# LPC176x5x register map
File version: 0.2
CPU: CM3 r0p0, little endian, no MPU, no FPU, 0x5 interrupt priority bits, 0x0 interrupts
Registers are 32-bit, read-write, no defined reset value unless marked. A register's access mark holds for its fields unless they carry their own. Offsets are from the block's base; [hi:lo] are bit positions; {n}, {i} and the like mark numbered series; <NAME> marks a mode.

## USB — USB device/host/OTG controller
Base 0x50008000
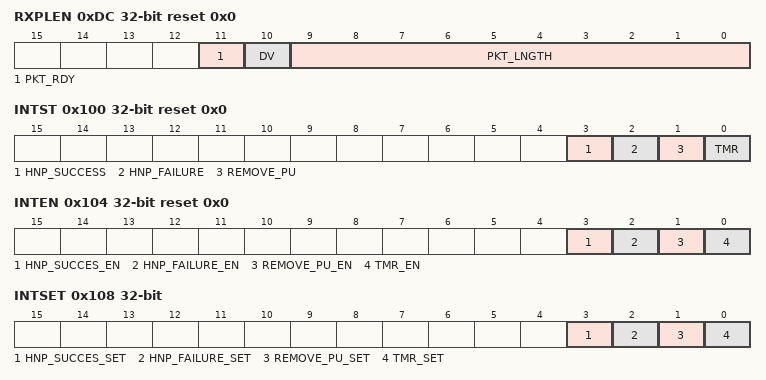
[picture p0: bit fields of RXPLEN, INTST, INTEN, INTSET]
0xDC RXPLEN ro reset 0x0 — USB Receive Packet Length
  [11] PKT_RDY — The PKT_LNGTH field is valid and the packet is ready for reading.
  [10] DV — Data valid. This bit is useful for isochronous endpoints. Non-isochronous endpoints do not raise an interrupt when an erroneous data packet is received. But invalid data packet can be produced with a bus reset. For isochronous endpoints, data transfer will happen even if an erroneous packet is received. In this case DV bit will not be set for the packet.
    0=DATA_IS_INVALID_; 1=DATA_IS_VALID_
  [9:0] PKT_LNGTH — The remaining number of bytes to be read from the currently selected endpoint's buffer. When this field decrements to 0, the RxENDPKT bit will be set in USBDevIntSt.
0x100 INTST ro reset 0x0 — OTG Interrupt Status
  [3] HNP_SUCCESS — HNP succeeded. This bit is set by hardware to indicate that the HNP switching has succeeded.
  [2] HNP_FAILURE — HNP failed. This bit is set by hardware to indicate that the HNP switching has failed.
  [1] REMOVE_PU — Remove pull-up. This bit is set by hardware to indicate that software needs to disable the D+ pull-up resistor.
  [0] TMR — Timer time-out.
0x104 INTEN reset 0x0 — OTG Interrupt Enable
  [3] HNP_SUCCES_EN — 1 = enable the corresponding bit in the IntSt register.
  [2] HNP_FAILURE_EN — 1 = enable the corresponding bit in the IntSt register.
  [1] REMOVE_PU_EN — 1 = enable the corresponding bit in the IntSt register.
  [0] TMR_EN — 1 = enable the corresponding bit in the IntSt register.
0x108 INTSET wo — OTG Interrupt Set
  [3] HNP_SUCCES_SET — 0 = no effect. 1 = set the corresponding bit in the IntSt register.
  [2] HNP_FAILURE_SET — 0 = no effect. 1 = set the corresponding bit in the IntSt register.
  [1] REMOVE_PU_SET — 0 = no effect. 1 = set the corresponding bit in the IntSt register.
  [0] TMR_SET — 0 = no effect. 1 = set the corresponding bit in the IntSt register.
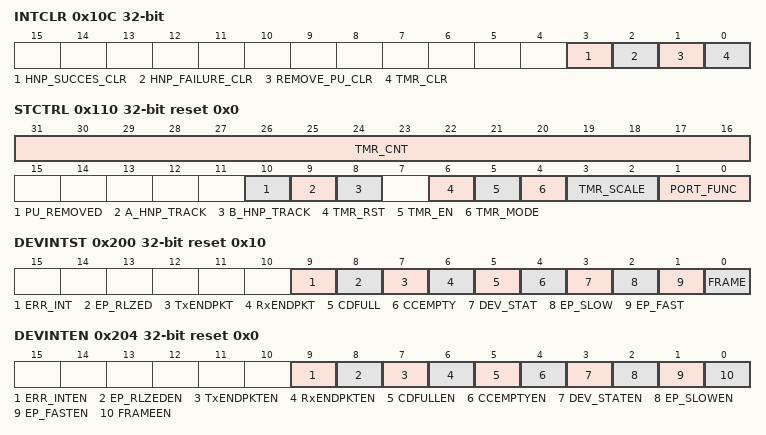
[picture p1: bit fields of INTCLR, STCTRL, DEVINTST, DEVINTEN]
0x10C INTCLR wo — OTG Interrupt Clear
  [3] HNP_SUCCES_CLR — 0 = no effect. 1 = clear the corresponding bit in the IntSt register.
  [2] HNP_FAILURE_CLR — 0 = no effect. 1 = clear the corresponding bit in the IntSt register.
  [1] REMOVE_PU_CLR — 0 = no effect. 1 = clear the corresponding bit in the IntSt register.
  [0] TMR_CLR — 0 = no effect. 1 = clear the corresponding bit in the IntSt register.
0x110 STCTRL reset 0x0 — OTG Status and Control and USB port select
  [31:16] TMR_CNT — Current timer count value.
  [10] PU_REMOVED — When the B-device changes its role from peripheral to host, software sets this bit when it removes the D+ pull-up, see Section 14.9. Hardware clears this bit when HNP_SUCCESS or HNP_FAILURE is set.
  [9] A_HNP_TRACK — Enable HNP tracking for A-device (host), see Section 14.9. Hardware clears this bit when HNP_SUCCESS or HNP_FAILURE is set.
  [8] B_HNP_TRACK — Enable HNP tracking for B-device (peripheral), see Section 14.9. Hardware clears this bit when HNP_SUCCESS or HNP_FAILURE is set.
  [6] TMR_RST — Timer reset. Writing one to this bit resets TMR_CNT to 0. This provides a single bit control for the software to restart the timer when the timer is enabled.
  [5] TMR_EN — Timer enable. When set, TMR_CNT increments. When cleared, TMR_CNT is reset to 0.
  [4] TMR_MODE — Timer mode selection. 0: monoshot 1: free running
  [3:2] TMR_SCALE — Timer scale selection. This field determines the duration of each timer count. 00: 10 ms (100 KHz) 01: 100 ms (10 KHz) 10: 1000 ms (1 KHz) 11: Reserved
  [1:0] PORT_FUNC — Controls connection of USB functions (see Figure 51). Bit 0 is set or cleared by hardware when B_HNP_TRACK or A_HNP_TRACK is set and HNP succeeds. See Section 14.9. 00: U1 = device (OTG), U2 = host 01: U1 = host (OTG), U2 = host 10: Reserved 11: U1 = host, U2 = device In a device-only configuration, the following values are allowed: 00: U1 = device. The USB device controller signals are mapped to the U1 port: USB_CONNECT1, USB_UP_LED1, USB_D+1, USB_D-1. 11: U2 = device. The USB device controller signals are mapped to the U2 port: USB_CONNECT2, USB_UP_LED2, USB_D+2, USB_D-2.
0x114 TMR reset 0xFFFF — OTG Timer
  [15:0] TIMEOUT_CNT — The TMR interrupt is set when TMR_CNT reaches this value.
0x200 DEVINTST ro reset 0x10 — USB Device Interrupt Status
  [9] ERR_INT — Error Interrupt. Any bus error interrupt from the USB device. Refer to Section 13.12.9 Read Error Status (Command: 0xFB, Data: read 1 byte) on page 368
  [8] EP_RLZED — Endpoints realized. Set when Realize Endpoint register (USBReEp) or MaxPacketSize register (USBMaxPSize) is updated and the corresponding operation is completed.
  [7] TxENDPKT — The number of data bytes transferred to the endpoint buffer equals the number of bytes programmed in the TxPacket length register (USBTxPLen).
  [6] RxENDPKT — The current packet in the endpoint buffer is transferred to the CPU.
  [5] CDFULL — Command data register (USBCmdData) is full (Data can be read now).
  [4] CCEMPTY — The command code register (USBCmdCode) is empty (New command can be written).
  [3] DEV_STAT — Set when USB Bus reset, USB suspend change or Connect change event occurs. Refer to Section 13.12.6 Set Device Status (Command: 0xFE, Data: write 1 byte) on page 366.
  [2] EP_SLOW — Slow endpoints interrupt. If an Endpoint Interrupt Priority Register (USBEpIntPri) bit is not set, the corresponding endpoint interrupt will be routed to this bit.
  [1] EP_FAST — Fast endpoint interrupt. If an Endpoint Interrupt Priority register (USBEpIntPri) bit is set, the corresponding endpoint interrupt will be routed to this bit.
  [0] FRAME — The frame interrupt occurs every 1 ms. This is used in isochronous packet transfers.
0x204 DEVINTEN reset 0x0 — USB Device Interrupt Enable
  [9] ERR_INTEN — 0 = No interrupt is generated. 1 = An interrupt will be generated when the corresponding bit in the Device Interrupt Status (USBDevIntSt) register (Table 261) is set. By default, the interrupt is routed to the USB_INT_REQ_LP interrupt line. Optionally, either the EP_FAST or FRAME interrupt may be routed to the USB_INT_REQ_HP interrupt line by changing the value of USBDevIntPri.
  [8] EP_RLZEDEN — 0 = No interrupt is generated. 1 = An interrupt will be generated when the corresponding bit in the Device Interrupt Status (USBDevIntSt) register (Table 261) is set. By default, the interrupt is routed to the USB_INT_REQ_LP interrupt line. Optionally, either the EP_FAST or FRAME interrupt may be routed to the USB_INT_REQ_HP interrupt line by changing the value of USBDevIntPri.
  [7] TxENDPKTEN — 0 = No interrupt is generated. 1 = An interrupt will be generated when the corresponding bit in the Device Interrupt Status (USBDevIntSt) register (Table 261) is set. By default, the interrupt is routed to the USB_INT_REQ_LP interrupt line. Optionally, either the EP_FAST or FRAME interrupt may be routed to the USB_INT_REQ_HP interrupt line by changing the value of USBDevIntPri.
  [6] RxENDPKTEN — 0 = No interrupt is generated. 1 = An interrupt will be generated when the corresponding bit in the Device Interrupt Status (USBDevIntSt) register (Table 261) is set. By default, the interrupt is routed to the USB_INT_REQ_LP interrupt line. Optionally, either the EP_FAST or FRAME interrupt may be routed to the USB_INT_REQ_HP interrupt line by changing the value of USBDevIntPri.
  [5] CDFULLEN — 0 = No interrupt is generated. 1 = An interrupt will be generated when the corresponding bit in the Device Interrupt Status (USBDevIntSt) register (Table 261) is set. By default, the interrupt is routed to the USB_INT_REQ_LP interrupt line. Optionally, either the EP_FAST or FRAME interrupt may be routed to the USB_INT_REQ_HP interrupt line by changing the value of USBDevIntPri.
  [4] CCEMPTYEN — 0 = No interrupt is generated. 1 = An interrupt will be generated when the corresponding bit in the Device Interrupt Status (USBDevIntSt) register (Table 261) is set. By default, the interrupt is routed to the USB_INT_REQ_LP interrupt line. Optionally, either the EP_FAST or FRAME interrupt may be routed to the USB_INT_REQ_HP interrupt line by changing the value of USBDevIntPri.
  [3] DEV_STATEN — 0 = No interrupt is generated. 1 = An interrupt will be generated when the corresponding bit in the Device Interrupt Status (USBDevIntSt) register (Table 261) is set. By default, the interrupt is routed to the USB_INT_REQ_LP interrupt line. Optionally, either the EP_FAST or FRAME interrupt may be routed to the USB_INT_REQ_HP interrupt line by changing the value of USBDevIntPri.
  [2] EP_SLOWEN — 0 = No interrupt is generated. 1 = An interrupt will be generated when the corresponding bit in the Device Interrupt Status (USBDevIntSt) register (Table 261) is set. By default, the interrupt is routed to the USB_INT_REQ_LP interrupt line. Optionally, either the EP_FAST or FRAME interrupt may be routed to the USB_INT_REQ_HP interrupt line by changing the value of USBDevIntPri.
  [1] EP_FASTEN — 0 = No interrupt is generated. 1 = An interrupt will be generated when the corresponding bit in the Device Interrupt Status (USBDevIntSt) register (Table 261) is set. By default, the interrupt is routed to the USB_INT_REQ_LP interrupt line. Optionally, either the EP_FAST or FRAME interrupt may be routed to the USB_INT_REQ_HP interrupt line by changing the value of USBDevIntPri.
  [0] FRAMEEN — 0 = No interrupt is generated. 1 = An interrupt will be generated when the corresponding bit in the Device Interrupt Status (USBDevIntSt) register (Table 261) is set. By default, the interrupt is routed to the USB_INT_REQ_LP interrupt line. Optionally, either the EP_FAST or FRAME interrupt may be routed to the USB_INT_REQ_HP interrupt line by changing the value of USBDevIntPri.
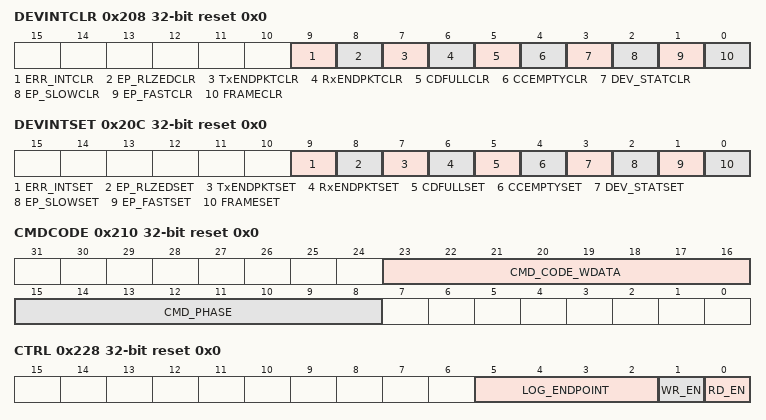
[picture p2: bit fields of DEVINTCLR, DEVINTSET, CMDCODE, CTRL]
0x208 DEVINTCLR wo reset 0x0 — USB Device Interrupt Clear
  [9] ERR_INTCLR — 0 = No effect. 1 = The corresponding bit in USBDevIntSt (Section 13.10.3.2) is cleared.
  [8] EP_RLZEDCLR — 0 = No effect. 1 = The corresponding bit in USBDevIntSt (Section 13.10.3.2) is cleared.
  [7] TxENDPKTCLR — 0 = No effect. 1 = The corresponding bit in USBDevIntSt (Section 13.10.3.2) is cleared.
  [6] RxENDPKTCLR — 0 = No effect. 1 = The corresponding bit in USBDevIntSt (Section 13.10.3.2) is cleared.
  [5] CDFULLCLR — 0 = No effect. 1 = The corresponding bit in USBDevIntSt (Section 13.10.3.2) is cleared.
  [4] CCEMPTYCLR — 0 = No effect. 1 = The corresponding bit in USBDevIntSt (Section 13.10.3.2) is cleared.
  [3] DEV_STATCLR — 0 = No effect. 1 = The corresponding bit in USBDevIntSt (Section 13.10.3.2) is cleared.
  [2] EP_SLOWCLR — 0 = No effect. 1 = The corresponding bit in USBDevIntSt (Section 13.10.3.2) is cleared.
  [1] EP_FASTCLR — 0 = No effect. 1 = The corresponding bit in USBDevIntSt (Section 13.10.3.2) is cleared.
  [0] FRAMECLR — 0 = No effect. 1 = The corresponding bit in USBDevIntSt (Section 13.10.3.2) is cleared.
0x20C DEVINTSET wo reset 0x0 — USB Device Interrupt Set
  [9] ERR_INTSET — 0 = No effect. 1 = The corresponding bit in USBDevIntSt (Section 13.10.3.2) is set.
  [8] EP_RLZEDSET — 0 = No effect. 1 = The corresponding bit in USBDevIntSt (Section 13.10.3.2) is set.
  [7] TxENDPKTSET — 0 = No effect. 1 = The corresponding bit in USBDevIntSt (Section 13.10.3.2) is set.
  [6] RxENDPKTSET — 0 = No effect. 1 = The corresponding bit in USBDevIntSt (Section 13.10.3.2) is set.
  [5] CDFULLSET — 0 = No effect. 1 = The corresponding bit in USBDevIntSt (Section 13.10.3.2) is set.
  [4] CCEMPTYSET — 0 = No effect. 1 = The corresponding bit in USBDevIntSt (Section 13.10.3.2) is set.
  [3] DEV_STATSET — 0 = No effect. 1 = The corresponding bit in USBDevIntSt (Section 13.10.3.2) is set.
  [2] EP_SLOWSET — 0 = No effect. 1 = The corresponding bit in USBDevIntSt (Section 13.10.3.2) is set.
  [1] EP_FASTSET — 0 = No effect. 1 = The corresponding bit in USBDevIntSt (Section 13.10.3.2) is set.
  [0] FRAMESET — 0 = No effect. 1 = The corresponding bit in USBDevIntSt (Section 13.10.3.2) is set.
0x210 CMDCODE wo reset 0x0 — USB Command Code
  [23:16] CMD_CODE_WDATA — This is a multi-purpose field. When CMD_PHASE is Command or Read, this field contains the code for the command (CMD_CODE). When CMD_PHASE is Write, this field contains the command write data (CMD_WDATA).
  [15:8] CMD_PHASE — The command phase:
    2=READ; 1=WRITE; 5=COMMAND
0x214 CMDDATA ro reset 0x0 — USB Command Data
  [7:0] CMD_RDATA — Command Read Data.
0x218 RXDATA ro reset 0x0 — USB Receive Data
  [31:0] RX_DATA — Data received.
0x21C TXDATA wo reset 0x0 — USB Transmit Data
  [31:0] TX_DATA — Transmit Data.
0x224 TXPLEN wo reset 0x0 — USB Transmit Packet Length
  [9:0] PKT_LNGTH — The remaining number of bytes to be written to the selected endpoint buffer. This field is decremented by 4 by hardware after each write to USBTxData. When this field decrements to 0, the TxENDPKT bit will be set in USBDevIntSt.
0x228 CTRL reset 0x0 — USB Control
  [5:2] LOG_ENDPOINT — Logical Endpoint number.
  [1] WR_EN — Write mode control. Enables writing data to the IN endpoint buffer for the endpoint specified in the LOG_ENDPOINT field using the USBTxData register. This bit is cleared by hardware when the number of bytes in USBTxLen have been sent.
    0=DISABLED_; 1=ENABLED_
  [0] RD_EN — Read mode control. Enables reading data from the OUT endpoint buffer for the endpoint specified in the LOG_ENDPOINT field using the USBRxData register. This bit is cleared by hardware when the last word of the current packet is read from USBRxData.
    0=DISABLED_; 1=ENABLED_
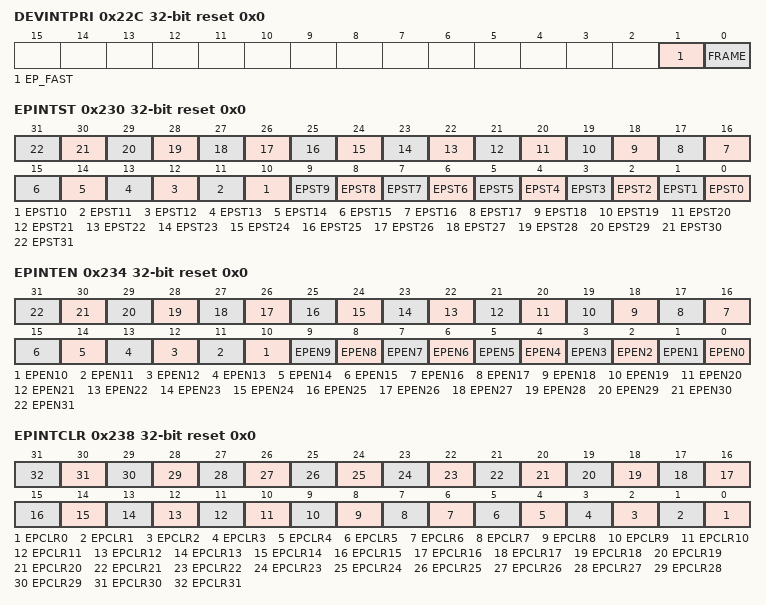
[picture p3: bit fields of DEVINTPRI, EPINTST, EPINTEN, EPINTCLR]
0x22C DEVINTPRI wo reset 0x0 — USB Device Interrupt Priority
  [1] EP_FAST — Fast endpoint interrupt routing
    0=LP (EP_FAST interrupt is routed to USB_INT_REQ_LP.); 1=HP (EP_FAST interrupt is routed to USB_INT_REQ_HP.)
  [0] FRAME — Frame interrupt routing
    0=LP (FRAME interrupt is routed to USB_INT_REQ_LP.); 1=HP (FRAME interrupt is routed to USB_INT_REQ_HP.)
0x230 EPINTST ro reset 0x0 — USB Endpoint Interrupt Status
  [n] EPST{n} (n=0..31) — 1 = Endpoint Data Received (bits 0, 2, 4, ..., 30) or Transmitted (bits 1, 3, 5, ..., 31) Interrupt received.
0x234 EPINTEN reset 0x0 — USB Endpoint Interrupt Enable
  [n] EPEN{n} (n=0..31) — 0= The corresponding bit in USBDMARSt is set when an interrupt occurs for this endpoint. 1 = The corresponding bit in USBEpIntSt is set when an interrupt occurs for this endpoint. Implies Slave mode for this endpoint.
0x238 EPINTCLR wo reset 0x0 — USB Endpoint Interrupt Clear
  [n] EPCLR{n} (n=0..31) — 0 = No effect. 1 = Clears the corresponding bit in USBEpIntSt, by executing the SIE Select Endpoint/Clear Interrupt command for this endpoint.
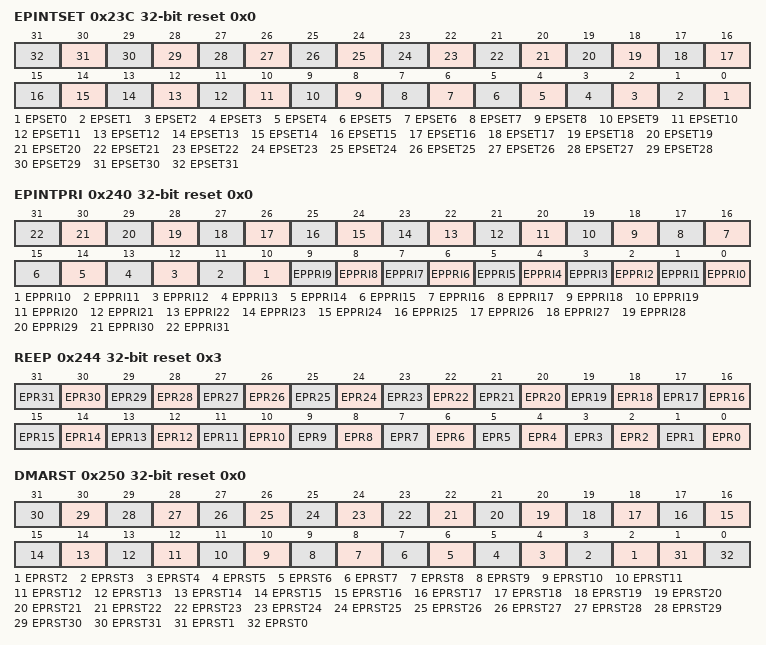
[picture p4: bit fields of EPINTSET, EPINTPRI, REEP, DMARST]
0x23C EPINTSET wo reset 0x0 — USB Endpoint Interrupt Set
  [n] EPSET{n} (n=0..31) — 0 = No effect. 1 = Sets the corresponding bit in USBEpIntSt.
0x240 EPINTPRI wo reset 0x0 — USB Endpoint Priority
  [n] EPPRI{n} (n=0..31) — 0 = The corresponding interrupt is routed to the EP_SLOW bit of USBDevIntSt 1 = The corresponding interrupt is routed to the EP_FAST bit of USBDevIntSt
0x244 REEP reset 0x3 — USB Realize Endpoint
  [n] EPR{n} (n=0..31) — 0 = Endpoint EPxx is not realized. 1 = Endpoint EPxx is realized.
0x248 EPIND wo reset 0x0 — USB Endpoint Index
  [4:0] PHY_EP — Physical endpoint number (0-31)
0x24C MAXPSIZE reset 0x8 — USB MaxPacketSize
  [9:0] MPS — The maximum packet size value.
0x250 DMARST ro reset 0x0 — USB DMA Request Status
  [n] EPRST{n} (n=2..31) — Endpoint xx (2 <= xx <= 31) DMA request. 0 = DMA not requested by endpoint xx. 1 = DMA requested by endpoint xx.
  [1] EPRST1 — Control endpoint IN (DMA cannot be enabled for this endpoint and EP1 bit must be 0).
  [0] EPRST0 — Control endpoint OUT (DMA cannot be enabled for this endpoint and EP0 bit must be 0).
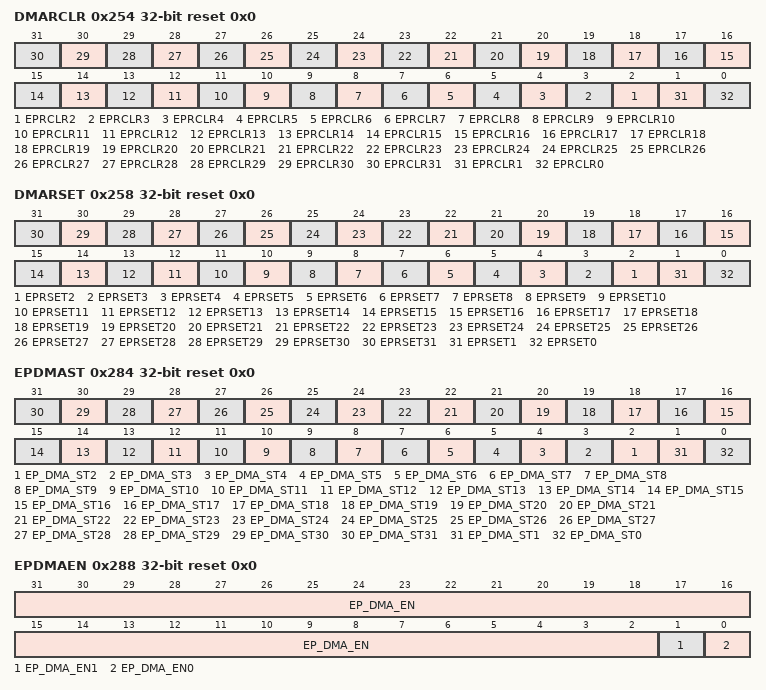
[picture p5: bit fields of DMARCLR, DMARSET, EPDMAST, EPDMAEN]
0x254 DMARCLR wo reset 0x0 — USB DMA Request Clear
  [n] EPRCLR{n} (n=2..31) — Clear the endpoint xx (2 <= xx <= 31) DMA request. 0 = No effect 1 = Clear the corresponding bit in USBDMARSt.
  [1] EPRCLR1 — Control endpoint IN (DMA cannot be enabled for this endpoint and the EP1 bit must be 0).
  [0] EPRCLR0 — Control endpoint OUT (DMA cannot be enabled for this endpoint and the EP0 bit must be 0).
0x258 DMARSET wo reset 0x0 — USB DMA Request Set
  [n] EPRSET{n} (n=2..31) — Set the endpoint xx (2 <= xx <= 31) DMA request. 0 = No effect 1 = Set the corresponding bit in USBDMARSt.
  [1] EPRSET1 — Control endpoint IN (DMA cannot be enabled for this endpoint and the EP1 bit must be 0).
  [0] EPRSET0 — Control endpoint OUT (DMA cannot be enabled for this endpoint and the EP0 bit must be 0).
0x280 UDCAH reset 0x0 — USB UDCA Head
  [31:7] UDCA_ADDR — Start address of the UDCA.
0x284 EPDMAST ro reset 0x0 — USB Endpoint DMA Status
  [n] EP_DMA_ST{n} (n=2..31) — Endpoint xx (2 <= xx <= 31) DMA enabled bit. 0 = The DMA for endpoint EPxx is disabled. 1 = The DMA for endpoint EPxx is enabled.
  [1] EP_DMA_ST1 — Control endpoint IN (DMA cannot be enabled for this endpoint and the EP1_DMA_ENABLE bit must be 0).
  [0] EP_DMA_ST0 — Control endpoint OUT (DMA cannot be enabled for this endpoint and the EP0_DMA_ENABLE bit must be 0).
0x288 EPDMAEN wo reset 0x0 — USB Endpoint DMA Enable
  [31:2] EP_DMA_EN — Endpoint xx(2 <= xx <= 31) DMA enable control bit. 0 = No effect. 1 = Enable the DMA operation for endpoint EPxx.
  [1] EP_DMA_EN1 — Control endpoint IN (DMA cannot be enabled for this endpoint and the EP1_DMA_ENABLE bit must be 0).
  [0] EP_DMA_EN0 — Control endpoint OUT (DMA cannot be enabled for this endpoint and the EP0_DMA_ENABLE bit value must be 0).
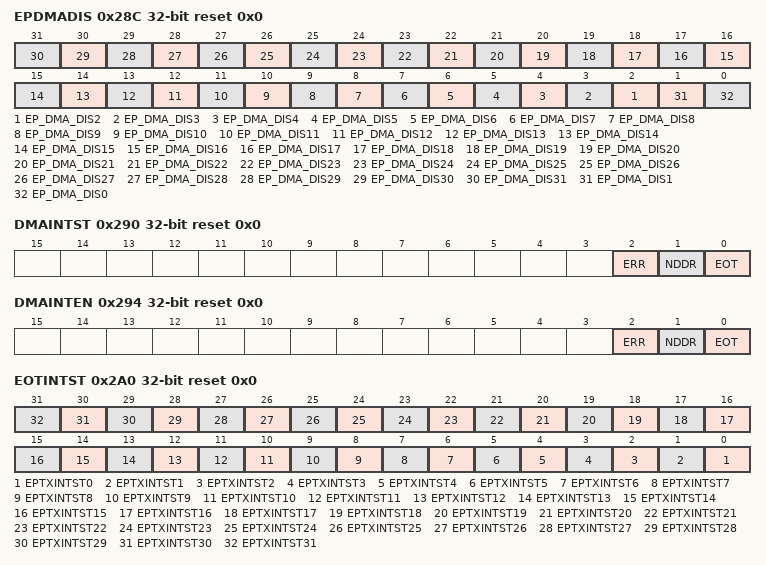
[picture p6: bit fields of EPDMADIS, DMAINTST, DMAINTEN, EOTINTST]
0x28C EPDMADIS wo reset 0x0 — USB Endpoint DMA Disable
  [n] EP_DMA_DIS{n} (n=2..31) — Endpoint xx (2 <= xx <= 31) DMA disable control bit. 0 = No effect. 1 = Disable the DMA operation for endpoint EPxx.
  [1] EP_DMA_DIS1 — Control endpoint IN (DMA cannot be enabled for this endpoint and the EP1_DMA_DISABLE bit value must be 0).
  [0] EP_DMA_DIS0 — Control endpoint OUT (DMA cannot be enabled for this endpoint and the EP0_DMA_DISABLE bit value must be 0).
0x290 DMAINTST ro reset 0x0 — USB DMA Interrupt Status
  [2] ERR — System Error Interrupt bit.
    0=ALL_BITS_IN_THE_USBS (All bits in the USBSysErrIntSt register are 0.); 1=AT_LEAST_ONE_BIT_IN_ (At least one bit in the USBSysErrIntSt is set.)
  [1] NDDR — New DD Request Interrupt bit.
    0=ALL_BITS_IN_THE_USBN (All bits in the USBNDDRIntSt register are 0.); 1=AT_LEAST_ONE_BIT_IN_ (At least one bit in the USBNDDRIntSt is set.)
  [0] EOT — End of Transfer Interrupt bit.
    0=ALL_BITS_IN_THE_USBE (All bits in the USBEoTIntSt register are 0.); 1=AT_LEAST_ONE_BIT_IN_ (At least one bit in the USBEoTIntSt is set.)
0x294 DMAINTEN reset 0x0 — USB DMA Interrupt Enable
  [all] fields
    0=DISABLED_; 1=ENABLED_
  [2] ERR — System Error Interrupt enable bit.
  [1] NDDR — New DD Request Interrupt enable bit.
  [0] EOT — End of Transfer Interrupt enable bit.
0x2A0 EOTINTST ro reset 0x0 — USB End of Transfer Interrupt Status
  [n] EPTXINTST{n} (n=0..31) — Endpoint xx (2 <= xx <= 31) End of Transfer Interrupt request. 0 = There is no End of Transfer interrupt request for endpoint xx. 1 = There is an End of Transfer Interrupt request for endpoint xx.
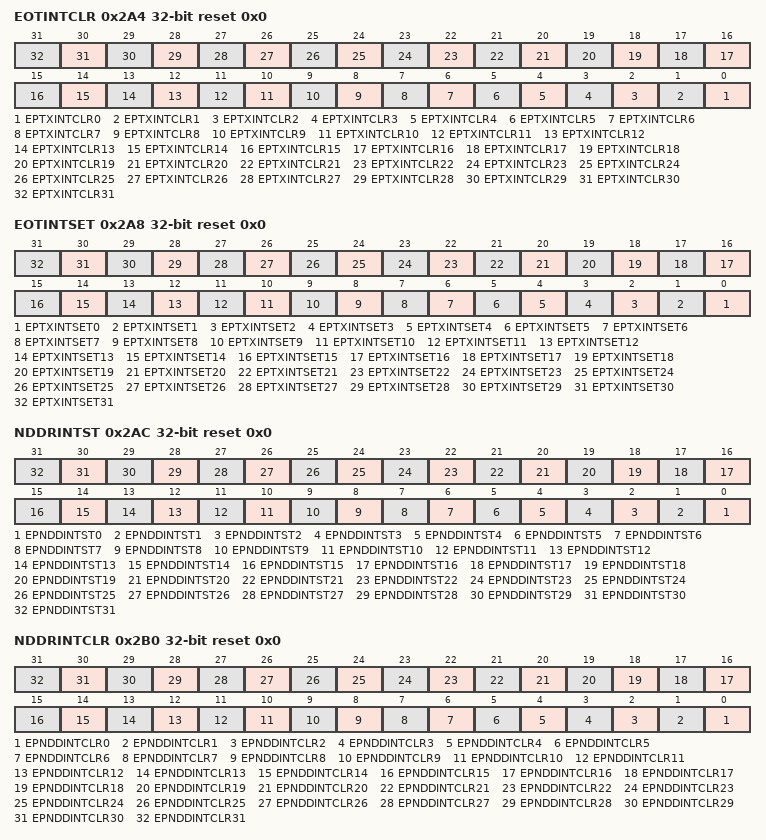
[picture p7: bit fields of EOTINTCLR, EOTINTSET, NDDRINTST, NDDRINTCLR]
0x2A4 EOTINTCLR wo reset 0x0 — USB End of Transfer Interrupt Clear
  [n] EPTXINTCLR{n} (n=0..31) — Clear endpoint xx (2 <= xx <= 31) End of Transfer Interrupt request. 0 = No effect. 1 = Clear the EPxx End of Transfer Interrupt request in the USBEoTIntSt register.
0x2A8 EOTINTSET wo reset 0x0 — USB End of Transfer Interrupt Set
  [n] EPTXINTSET{n} (n=0..31) — Set endpoint xx (2 <= xx <= 31) End of Transfer Interrupt request. 0 = No effect. 1 = Set the EPxx End of Transfer Interrupt request in the USBEoTIntSt register.
0x2AC NDDRINTST ro reset 0x0 — USB New DD Request Interrupt Status
  [n] EPNDDINTST{n} (n=0..31) — Endpoint xx (2 <= xx <= 31) new DD interrupt request. 0 = There is no new DD interrupt request for endpoint xx. 1 = There is a new DD interrupt request for endpoint xx.
0x2B0 NDDRINTCLR wo reset 0x0 — USB New DD Request Interrupt Clear
  [n] EPNDDINTCLR{n} (n=0..31) — Clear endpoint xx (2 <= xx <= 31) new DD interrupt request. 0 = No effect. 1 = Clear the EPxx new DD interrupt request in the USBNDDRIntSt register.
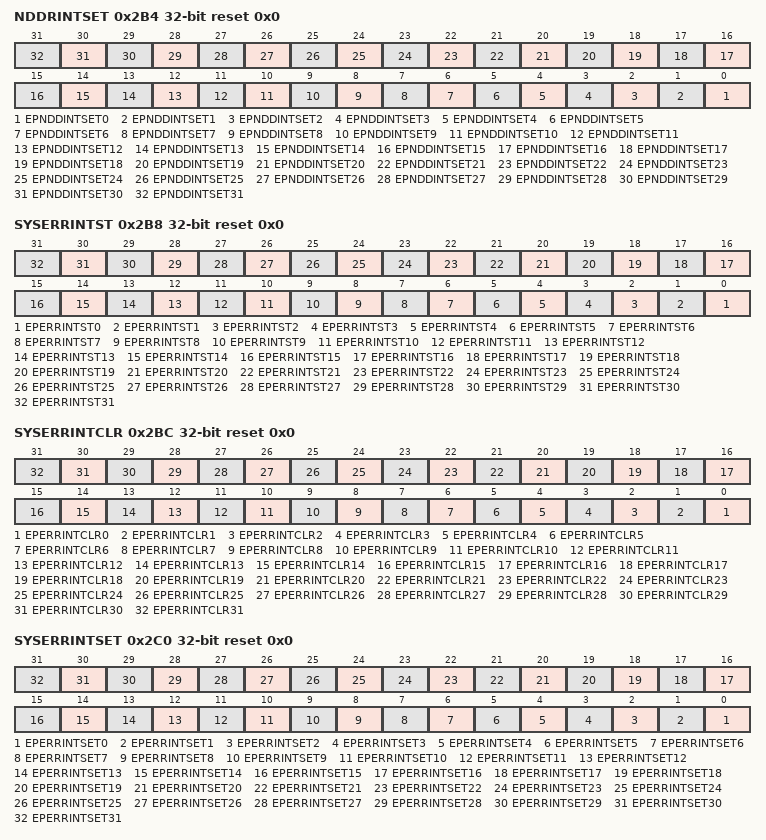
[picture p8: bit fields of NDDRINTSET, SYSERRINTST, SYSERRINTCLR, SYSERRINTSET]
0x2B4 NDDRINTSET wo reset 0x0 — USB New DD Request Interrupt Set
  [n] EPNDDINTSET{n} (n=0..31) — Set endpoint xx (2 <= xx <= 31) new DD interrupt request. 0 = No effect. 1 = Set the EPxx new DD interrupt request in the USBNDDRIntSt register.
0x2B8 SYSERRINTST ro reset 0x0 — USB System Error Interrupt Status
  [n] EPERRINTST{n} (n=0..31) — Endpoint xx (2 <= xx <= 31) System Error Interrupt request. 0 = There is no System Error Interrupt request for endpoint xx. 1 = There is a System Error Interrupt request for endpoint xx.
0x2BC SYSERRINTCLR wo reset 0x0 — USB System Error Interrupt Clear
  [n] EPERRINTCLR{n} (n=0..31) — Clear endpoint xx (2 <= xx <= 31) System Error Interrupt request. 0 = No effect. 1 = Clear the EPxx System Error Interrupt request in the USBSysErrIntSt register.
0x2C0 SYSERRINTSET wo reset 0x0 — USB System Error Interrupt Set
  [n] EPERRINTSET{n} (n=0..31) — Set endpoint xx (2 <= xx <= 31) System Error Interrupt request. 0 = No effect. 1 = Set the EPxx System Error Interrupt request in the USBSysErrIntSt register.
0x300 I2C_RX ro — I2C Receive
  [7:0] RXDATA — Receive data.
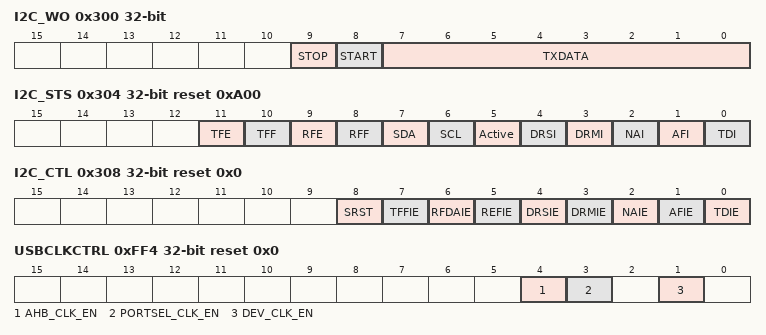
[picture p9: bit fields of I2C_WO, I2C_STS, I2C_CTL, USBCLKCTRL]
0x300 I2C_WO wo — I2C Transmit
  [9] STOP — When 1, issue a STOP condition after transmitting this byte.
  [8] START — When 1, issue a START condition before transmitting this byte.
  [7:0] TXDATA — Transmit data.
0x304 I2C_STS ro reset 0xA00 — I2C Status
  [11] TFE — Transmit FIFO Empty. TFE is set when the TX FIFO is empty and is cleared when the TX FIFO contains valid data.
    0=VALID_DATA (TX FIFO contains valid data.); 1=EMPTY (TX FIFO is empty)
  [10] TFF — Transmit FIFO Full. TFF is set when the TX FIFO is full and is cleared when the TX FIFO is not full.
    0=TX_FIFO_IS_NOT_FULL_; 1=TX_FIFO_IS_FULL
  [9] RFE — Receive FIFO Empty. RFE is set when the RX FIFO is empty and is cleared when the RX FIFO contains valid data.
    0=DATA (RX FIFO contains data.); 1=EMPTY (RX FIFO is empty)
  [8] RFF — Receive FIFO Full (RFF). This bit is set when the RX FIFO is full and cannot accept any more data. It is cleared when the RX FIFO is not full. If a byte arrives when the Receive FIFO is full, the SCL is held low until the CPU reads the RX FIFO and makes room for it.
    0=RX_FIFO_IS_NOT_FULL; 1=RX_FIFO_IS_FULL
  [7] SDA — The current value of the SDA signal.
  [6] SCL — The current value of the SCL signal.
  [5] Active — Indicates whether the bus is busy. This bit is set when a START condition has been seen. It is cleared when a STOP condition is seen..
  [4] DRSI — Slave Data Request Interrupt. Once a transmission is started, the transmitter must have data to transmit as long as it isn't followed by a STOP condition or it will hold SCL low until more data is available. The Slave Data Request bit is set when the slave transmitter is data-starved. If the slave TX FIFO is empty and the last byte transmitted was acknowledged, then SCL is held low until the CPU writes another byte to transmit. This bit is cleared when a byte is written to the slave Tx FIFO.
    0=BUSY (Slave transmitter does not need data.); 1=NEED_DATA (Slave transmitter needs data.)
  [3] DRMI — Master Data Request Interrupt. Once a transmission is started, the transmitter must have data to transmit as long as it isn't followed by a stop condition or it will hold SCL low until more data is available. The Master Data Request bit is set when the master transmitter is data-starved. If the master TX FIFO is empty and the last byte did not have a STOP condition flag, then SCL is held low until the CPU writes another byte to transmit. This bit is cleared when a byte is written to the master TX FIFO.
    0=BUSY (Master transmitter does not need data.); 1=NEED_DATA (Master transmitter needs data.)
  [2] NAI — No Acknowledge Interrupt. After every byte of data is sent, the transmitter expects an acknowledge from the receiver. This bit is set if the acknowledge is not received. It is cleared when a byte is written to the master TX FIFO.
    0=ACKNOWLEDGE_RCVD (Last transmission received an acknowledge.); 1=NO_ACKNOWLEDGE_RCVD (Last transmission did not receive an acknowledge.)
  [1] AFI — Arbitration Failure Interrupt. When transmitting, if the SDA is low when SDAOUT is high, then this I2C has lost the arbitration to another device on the bus. The Arbitration Failure bit is set when this happens. It is cleared by writing a one to bit 1 of the status register.
    0=NO_ARBITRATION_FAILU (No arbitration failure on last transmission.); 1=ARBITRATION_FAILURE_ (Arbitration failure occurred on last transmission.)
  [0] TDI — Transaction Done Interrupt. This flag is set if a transaction completes successfully. It is cleared by writing a one to bit 0 of the status register. It is unaffected by slave transactions.
    0=NOT_COMPLETE (Transaction has not completed.); 1=COMPLETE (Transaction completed.)
0x308 I2C_CTL reset 0x0 — I2C Control
  [8] SRST — Soft reset. This is only needed in unusual circumstances. If a device issues a start condition without issuing a stop condition. A system timer may be used to reset the I2C if the bus remains busy longer than the time-out period. On a soft reset, the Tx and Rx FIFOs are flushed, I2C_STS register is cleared, and all internal state machines are reset to appear idle. The I2C_CLKHI, I2C_CLKLO and I2C_CTL (except Soft Reset Bit) are NOT modified by a soft reset.
    0=NO_RESET; 1=RESET (Reset the I2C to idle state. Self clearing.)
  [7] TFFIE — Transmit FIFO Not Full Interrupt Enable. This enables the Transmit FIFO Not Full interrupt to indicate that the more data can be written to the transmit FIFO. Note that this is not full. It is intended help the CPU to write to the I2C block only when there is room in the FIFO and do this without polling the status register.
    0=DISABLE_THE_TFFI_; 1=ENABLE_THE_TFFI_
  [6] RFDAIE — Receive Data Available Interrupt Enable. This enables the DAI interrupt to indicate that data is available in the receive FIFO (i.e. not empty).
    0=DISABLE_THE_DAI_; 1=ENABLE_THE_DAI_
  [5] REFIE — Receive FIFO Full Interrupt Enable. This enables the Receive FIFO Full interrupt to indicate that the receive FIFO cannot accept any more data.
    0=DISABLE_THE_RFFI_; 1=ENABLE_THE_RFFI_
  [4] DRSIE — Slave Transmitter Data Request Interrupt Enable. This enables the DRSI interrupt which signals that the slave transmitter has run out of data and the last byte was acknowledged, so the SCL line is being held low.
    0=DISABLE_THE_DRSI_INT (Disable the DRSI interrupt.); 1=ENABLE_THE_DRSI_INTE (Enable the DRSI interrupt.)
  [3] DRMIE — Master Transmitter Data Request Interrupt Enable. This enables the DRMI interrupt which signals that the master transmitter has run out of data, has not issued a STOP, and is holding the SCL line low.
    0=DISABLE_THE_DRMI_INT (Disable the DRMI interrupt.); 1=ENABLE_THE_DRMI_INTE (Enable the DRMI interrupt.)
  [2] NAIE — Transmitter No Acknowledge Interrupt Enable. This enables the NAI interrupt signalling that transmitted byte was not acknowledged.
    0=DISABLE_THE_NAI_; 1=ENABLE_THE_NAI_
  [1] AFIE — Transmitter Arbitration Failure Interrupt Enable. This enables the AFI interrupt which is asserted during transmission when trying to set SDA high, but the bus is driven low by another device.
    0=DISABLE_THE_AFI_; 1=ENABLE_THE_AFI_
  [0] TDIE — Transmit Done Interrupt Enable. This enables the TDI interrupt signalling that this I2C issued a STOP condition.
    0=DISABLE_THE_TDI_INTE (Disable the TDI interrupt.); 1=ENABLE_THE_TDI_INTER (Enable the TDI interrupt.)
0x30C I2C_CLKHI reset 0xB9 — I2C Clock High
  [7:0] CDHI — Clock divisor high. This value is the number of 48 MHz clocks the serial clock (SCL) will be high.
0x310 I2C_CLKLO wo reset 0xB9 — I2C Clock Low
  [7:0] CDLO — Clock divisor low. This value is the number of 48 MHz clocks the serial clock (SCL) will be low.
0xFF4 USBCLKCTRL reset 0x0 — USB Clock Control
  [4] AHB_CLK_EN — AHB clock enable
  [3] PORTSEL_CLK_EN — Port select register clock enable.
  [1] DEV_CLK_EN — Device clock enable. Enables the usbclk input to the device controller
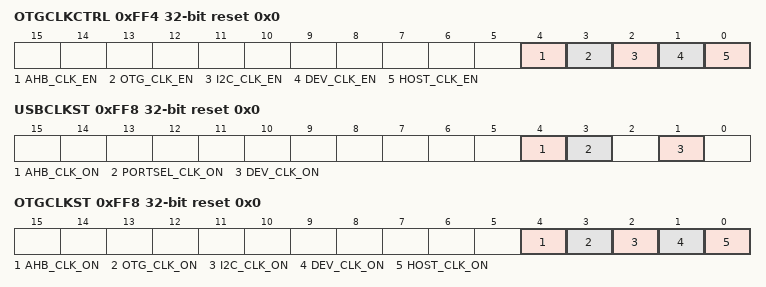
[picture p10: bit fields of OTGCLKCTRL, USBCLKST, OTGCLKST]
0xFF4 OTGCLKCTRL reset 0x0 — OTG clock controller
  [4] AHB_CLK_EN — AHB master clock enable
    0=DISABLE_THE_AHB_CLOC (Disable the AHB clock.); 1=ENABLE_THE_AHB_CLOCK
  [3] OTG_CLK_EN — OTG clock enable. In device-only applications, this bit enables access to the PORTSEL register.
    0=DISABLE_THE_OTG_CLOC (Disable the OTG clock.); 1=ENABLE_THE_OTG_CLOCK
  [2] I2C_CLK_EN — I2C clock enable
    0=DISABLE_THE_I2C_CLOC (Disable the I2C clock.); 1=ENABLE_THE_I2C_CLOCK
  [1] DEV_CLK_EN — Device clock enable
    0=DISABLE_THE_DEVICE_C (Disable the Device clock.); 1=ENABLE_THE_DEVICE_CL (Enable the Device clock.)
  [0] HOST_CLK_EN — Host clock enable
    0=DISABLE_THE_HOST_CLO (Disable the Host clock.); 1=ENABLE_THE_HOST_CLOC (Enable the Host clock.)
0xFF8 USBCLKST ro reset 0x0 — USB Clock Status
  [4] AHB_CLK_ON — AHB clock on.
  [3] PORTSEL_CLK_ON — Port select register clock on.
  [1] DEV_CLK_ON — Device clock on. The usbclk input to the device controller is active .
0xFF8 OTGCLKST ro reset 0x0 — OTG clock status
  [4] AHB_CLK_ON — AHB master clock status.
    0=AHB_CLOCK_IS_NOT_AVA (AHB clock is not available.); 1=AHB_CLOCK_IS_AVAILAB (AHB clock is available.)
  [3] OTG_CLK_ON — OTG clock status.
    0=OTG_CLOCK_IS_NOT_AVA (OTG clock is not available.); 1=OTG_CLOCK_IS_AVAILAB (OTG clock is available.)
  [2] I2C_CLK_ON — I2C clock status.
    0=I2C_CLOCK_IS_NOT_AVA (I2C clock is not available.); 1=I2C_CLOCK_IS_AVAILAB (I2C clock is available.)
  [1] DEV_CLK_ON — Device clock status.
    0=DEVICE_CLOCK_IS_NOT_ (Device clock is not available.); 1=DEVICE_CLOCK_IS_AVAI (Device clock is available.)
  [0] HOST_CLK_ON — Host clock status.
    0=HOST_CLOCK_IS_NOT_AV (Host clock is not available.); 1=HOST_CLOCK_IS_AVAILA (Host clock is available.)
